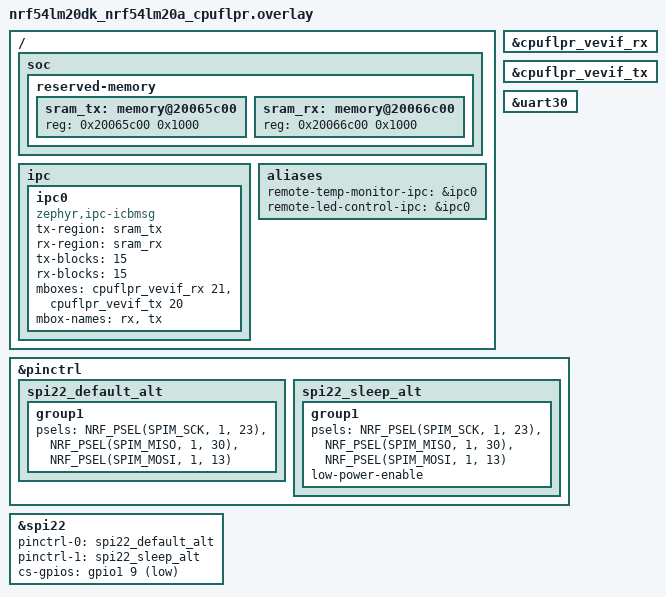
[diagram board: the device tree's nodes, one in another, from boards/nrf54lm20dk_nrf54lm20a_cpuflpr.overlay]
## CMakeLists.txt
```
#
# Copyright (c) 2026 Nordic Semiconductor ASA
#
# SPDX-License-Identifier: LicenseRef-Nordic-5-Clause
#

cmake_minimum_required(VERSION 3.20.0)

find_package(Zephyr REQUIRED HINTS $ENV{ZEPHYR_BASE})
project(remote_vpr_offloading)

target_sources(app PRIVATE src/main.c ../common/ipc_comm.c ../common/temp_monitor.c ../common/led_control.c)
```

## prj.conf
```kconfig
# Copyright (c) 2026 Nordic Semiconductor ASA
# SPDX-License-Identifier: LicenseRef-Nordic-5-Clause
CONFIG_GPIO=y
CONFIG_GPIO_NRFX_INTERRUPT=n

# Boot
CONFIG_BOOT_BANNER=n
CONFIG_NCS_BOOT_BANNER=n

CONFIG_IPC_SERVICE=y
CONFIG_MBOX=y

# Single-threaded
CONFIG_MULTITHREADING=n
CONFIG_KERNEL_MEM_POOL=n

# Interrupts
CONFIG_DYNAMIC_INTERRUPTS=n
CONFIG_IRQ_OFFLOAD=n
CONFIG_GEN_SW_ISR_TABLE=n

CONFIG_NRFX_SPIM=y
CONFIG_PINCTRL=y

CONFIG_TEST_RANDOM_GENERATOR=y
CONFIG_TIMER_RANDOM_GENERATOR=y

CONFIG_LOG=n
CONFIG_SERIAL=n
CONFIG_PRINTK=n
CONFIG_CONSOLE=n
CONFIG_UART_CONSOLE=n
CONFIG_LOG_PRINTK=n
```

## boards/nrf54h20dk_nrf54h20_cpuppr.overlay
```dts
/*
 * Copyright (c) 2026 Nordic Semiconductor ASA
 * SPDX-License-Identifier: LicenseRef-Nordic-5-Clause
 */

&cpuppr_vevif_rx {
	/* Only 1 interrupt is used. Remove 15 not used isr handlers (1.4k savings) */
	interrupts = <12 NRF_DEFAULT_IRQ_PRIORITY>;
	nordic,tasks = <1>;
};

&uart135 {
	/delete-property/ hw-flow-control;
};

/ {
	leds {
		compatible = "gpio-leds";

		led0: led_0 {
			gpios = <&gpio9 0x0 0x0>;
		};
	};

	aliases {
		remote-temp-monitor-ipc = &cpuapp_cpuppr_ipc;
		remote-led-control-ipc = &cpuapp_cpuppr_ipc;
		led0 = &led0;
	};
};

&pinctrl {
	spi130_default_alt: spi130_default_alt {
		group1 {
			psels = <NRF_PSEL(SPIM_SCK, 1, 3)>,
				<NRF_PSEL(SPIM_MISO, 1, 5)>,
				<NRF_PSEL(SPIM_MOSI, 1, 4)>;
		};
	};

	spi130_sleep_alt: spi130_sleep_alt {
		group1 {
			psels = <NRF_PSEL(SPIM_SCK, 1, 3)>,
				<NRF_PSEL(SPIM_MISO, 1, 5)>,
				<NRF_PSEL(SPIM_MOSI, 1, 4)>;
			low-power-enable;
		};
	};
};

&gpio9 {
	status = "okay";
	/delete-property/ gpiote-instance;
};

&gpiote130 {
	status = "okay";
};

app_spi: &spi130 {
	status = "okay";
	pinctrl-0 = <&spi130_default_alt>;
	pinctrl-1 = <&spi130_sleep_alt>;
	pinctrl-names = "default", "sleep";
	cs-gpios = <&gpio1 6 GPIO_ACTIVE_LOW>;
};
```

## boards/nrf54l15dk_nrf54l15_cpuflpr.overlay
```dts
/*
 * Copyright (c) 2026 Nordic Semiconductor ASA
 *
 * SPDX-License-Identifier: LicenseRef-Nordic-5-Clause
 */

/ {
	aliases {
		remote-temp-monitor-ipc = &ipc0;
		remote-led-control-ipc = &ipc0;
	};
};

&uart30 {
	/delete-property/ hw-flow-control;
};

&pinctrl {
	spi22_default_alt: spi22_default_alt {
		group1 {
			psels = <NRF_PSEL(SPIM_SCK, 1, 8)>,
				<NRF_PSEL(SPIM_MISO, 1, 10)>,
				<NRF_PSEL(SPIM_MOSI, 1, 9)>;
		};
	};

	spi22_sleep_alt: spi22_sleep_alt {
		group1 {
			psels = <NRF_PSEL(SPIM_SCK, 1, 8)>,
				<NRF_PSEL(SPIM_MISO, 1, 10)>,
				<NRF_PSEL(SPIM_MOSI, 1, 9)>;
			low-power-enable;
		};
	};
};

app_spi: &spi22 {
	status = "okay";
	pinctrl-0 = <&spi22_default_alt>;
	pinctrl-1 = <&spi22_sleep_alt>;
	pinctrl-names = "default", "sleep";
	overrun-character = <0x00>;
	cs-gpios = <&gpio1 11 GPIO_ACTIVE_LOW>;
};
```

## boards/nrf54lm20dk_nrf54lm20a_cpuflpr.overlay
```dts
/*
 * Copyright (c) 2026 Nordic Semiconductor ASA
 *
 * SPDX-License-Identifier: LicenseRef-Nordic-5-Clause
 */

/ {
	soc {
		reserved-memory {
			#address-cells = <1>;
			#size-cells = <1>;

			sram_tx: memory@20065c00 {
				reg = <0x20065c00 0x1000>;
			};

			sram_rx: memory@20066c00 {
				reg = <0x20066c00 0x1000>;
			};
		};
	};

	ipc {
		ipc0: ipc0 {
			compatible = "zephyr,ipc-icbmsg";
			tx-region = <&sram_tx>;
			rx-region = <&sram_rx>;
			tx-blocks = <15>;
			rx-blocks = <15>;
			mboxes = <&cpuflpr_vevif_rx 21>, <&cpuflpr_vevif_tx 20>;
			mbox-names = "rx", "tx";
			status = "okay";
		};
	};

	aliases {
		remote-temp-monitor-ipc = &ipc0;
		remote-led-control-ipc = &ipc0;
	};
};

&cpuflpr_vevif_rx {
	status = "okay";
};

&cpuflpr_vevif_tx {
	status = "okay";
};

&uart30 {
	/delete-property/ hw-flow-control;
};

&pinctrl {
	spi22_default_alt: spi22_default_alt {
		group1 {
			psels = <NRF_PSEL(SPIM_SCK, 1, 23)>,
				<NRF_PSEL(SPIM_MISO, 1, 30)>,
				<NRF_PSEL(SPIM_MOSI, 1, 13)>;
		};
	};

	spi22_sleep_alt: spi22_sleep_alt {
		group1 {
			psels = <NRF_PSEL(SPIM_SCK, 1, 23)>,
				<NRF_PSEL(SPIM_MISO, 1, 30)>,
				<NRF_PSEL(SPIM_MOSI, 1, 13)>;
			low-power-enable;
		};
	};
};

app_spi: &spi22 {
	status = "okay";
	pinctrl-0 = <&spi22_default_alt>;
	pinctrl-1 = <&spi22_sleep_alt>;
	pinctrl-names = "default", "sleep";
	cs-gpios = <&gpio1 9 GPIO_ACTIVE_LOW>;
};
```

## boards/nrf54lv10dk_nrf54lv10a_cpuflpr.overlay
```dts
/*
 * Copyright (c) 2026 Nordic Semiconductor ASA
 *
 * SPDX-License-Identifier: LicenseRef-Nordic-5-Clause
 */

/ {
	aliases {
		remote-temp-monitor-ipc = &ipc0;
		remote-led-control-ipc = &ipc0;
	};
};

&pinctrl {
	spi21_default_alt: spi21_default_alt {
		group1 {
			psels = <NRF_PSEL(SPIM_SCK, 1, 19)>,
				<NRF_PSEL(SPIM_MISO, 1, 20)>,
				<NRF_PSEL(SPIM_MOSI, 1, 21)>;
		};
	};

	spi21_sleep_alt: spi21_sleep_alt {
		group1 {
			psels = <NRF_PSEL(SPIM_SCK, 1, 19)>,
				<NRF_PSEL(SPIM_MISO, 1, 20)>,
				<NRF_PSEL(SPIM_MOSI, 1, 21)>;
			low-power-enable;
		};
	};
};

app_spi: &spi21 {
	status = "okay";
	pinctrl-0 = <&spi21_default_alt>;
	pinctrl-1 = <&spi21_sleep_alt>;
	pinctrl-names = "default", "sleep";
	overrun-character = <0x00>;
	cs-gpios = <&gpio1 22 GPIO_ACTIVE_LOW>;
};
```

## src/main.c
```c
/*
 * Copyright (c) 2026 Nordic Semiconductor ASA
 *
 * SPDX-License-Identifier: LicenseRef-Nordic-5-Clause
 */

#include <zephyr/kernel.h>
#include <zephyr/init.h>
#include <zephyr/logging/log.h>
#include <zephyr/logging/log_ctrl.h>
LOG_MODULE_REGISTER(app);

int main(void)
{
#if !defined(CONFIG_MULTITHREADING)
	while (1) {
		while (LOG_PROCESS()) {
		}
		k_cpu_idle();
	}
#else
	k_sleep(K_FOREVER);
#endif

	return 0;
}
```
